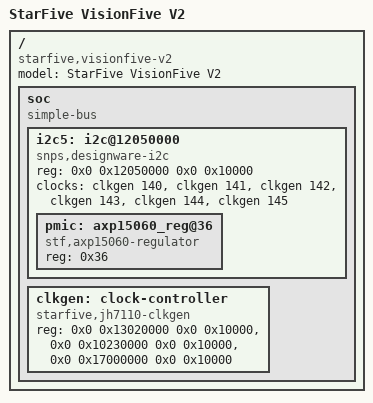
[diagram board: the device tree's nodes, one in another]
/dts-v1/;

/*
 * A PMIC bus that names more usable clock gates than `MAX_PMIC_BUS_STEPS` holds, and no `resets`
 * property at all (a mutation-survivor triage fixture, provisional name). Hand-written, not a
 * dump from any board: six real SYS-domain gates in `clocks` (140 to 145) on the bus node radon's
 * tree uses, so the plan must keep the first four, say it was cut short, and still be the tree's
 * own. A bus with `clocks` and without `resets` is also the case where "both properties absent"
 * and "either property absent" part ways.
 *
 * Regenerate with:
 *
 *     dtc -I dts -O dtb -o crates/machine_discovery/tests/fixtures/jh7110-pmic-bus-overfull.dtb \
 *                          crates/machine_discovery/tests/fixtures/jh7110-pmic-bus-overfull.dts
 */

/ {
	#address-cells = <2>;
	#size-cells = <2>;
	compatible = "starfive,visionfive-v2", "starfive,jh7110";
	model = "StarFive VisionFive V2";

	soc {
		compatible = "simple-bus";
		#address-cells = <2>;
		#size-cells = <2>;
		ranges;

		i2c5: i2c@12050000 {
			compatible = "snps,designware-i2c";
			reg = <0x0 0x12050000 0x0 0x10000>;
			clocks = <&clkgen 140>, <&clkgen 141>, <&clkgen 142>,
			         <&clkgen 143>, <&clkgen 144>, <&clkgen 145>;
			clock-names = "a", "b", "c", "d", "e", "f";
			#address-cells = <1>;
			#size-cells = <0>;
			status = "okay";

			pmic: axp15060_reg@36 {
				compatible = "stf,axp15060-regulator";
				reg = <0x36>;
			};
		};

		clkgen: clock-controller {
			compatible = "starfive,jh7110-clkgen";
			reg = <0x0 0x13020000 0x0 0x10000>,
			      <0x0 0x10230000 0x0 0x10000>,
			      <0x0 0x17000000 0x0 0x10000>;
			reg-names = "sys", "stg", "aon";
			#clock-cells = <1>;
			status = "okay";
		};
	};
};
